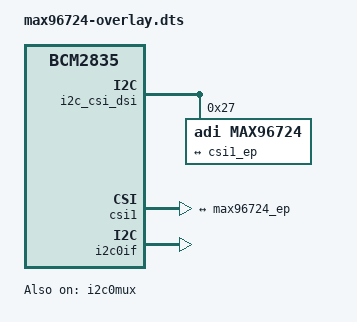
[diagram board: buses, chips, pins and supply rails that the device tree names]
// Definitions for MAX96724 deserializer
/dts-v1/;
/plugin/;

/{
	compatible = "brcm,bcm2835";

	fragment@0 {
		target = <&i2c_csi_dsi>;
		__overlay__ {
			#address-cells = <1>;
			#size-cells = <0>;
			status = "okay";

			max96724@27 {
				compatible = "adi,max96724";
				reg = <0x27>;
				status = "okay";

				port {
					max96724_ep: endpoint {
						remote-endpoint = <&csi1_ep>;
						clock-lanes = <0>;
						data-lanes = <1 2>;
					};
				};
			};
		};
	};

	fragment@1 {
		target = <&csi1>;
		__overlay__ {
			status = "okay";
			brcm,media-controller;

			port {
				csi1_ep: endpoint {
					remote-endpoint = <&max96724_ep>;
					data-lanes = <1 2>;
				};
			};
		};
	};

	fragment@2 {
		target = <&i2c0if>;
		__overlay__ {
			status = "okay";
		};
	};

	fragment@3 {
		target = <&i2c0mux>;
		__overlay__ {
			status = "okay";
		};
	};
};
